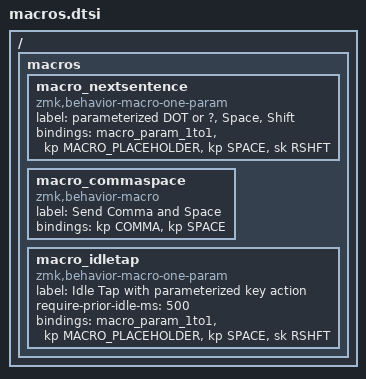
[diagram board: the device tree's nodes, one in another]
/ {
    macros {
        macro_nextsentence: macro_nextsentence {
            label = "parameterized DOT or ?, Space, Shift";
            compatible = "zmk,behavior-macro-one-param";
            bindings = <&macro_param_1to1 &kp MACRO_PLACEHOLDER>, <&kp SPACE &sk RSHFT>;
            #binding-cells = <1>;
        };

        macro_commaspace: macro_commaspace {
            label = "Send Comma and Space";
            compatible = "zmk,behavior-macro";
            bindings = <&kp COMMA &kp SPACE>;
            #binding-cells = <0>;
        };

        // macro to avoid accidental presses on certain keys
        macro_idletap: macro_idletap {
            label = "Idle Tap with parameterized key action";
            compatible = "zmk,behavior-macro-one-param";
            require-prior-idle-ms = <500>;    // Add idle time requirement
           // bindings = <&kp &macro_param_1to1>;   // Key action as a parameter
            bindings = <&macro_param_1to1 &kp MACRO_PLACEHOLDER>, <&kp SPACE &sk RSHFT>;
            #binding-cells = <1>;
        };
    };
};
